VERSION ""

NS_ :

BS_:

BU_: ECU_CHASSIS ECU_ACTUATOR

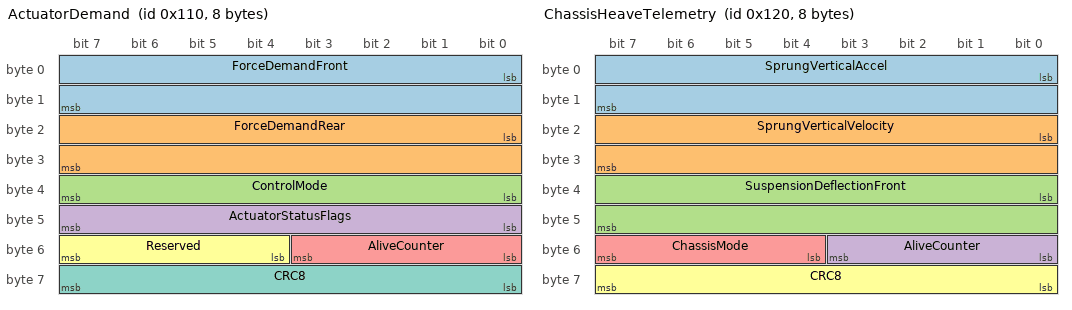
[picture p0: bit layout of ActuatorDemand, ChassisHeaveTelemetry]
BO_ 272 ActuatorDemand: 8 ECU_CHASSIS
 SG_ ForceDemandFront : 0|16@1- (0.1,0) [-2500|2500] "N" ECU_ACTUATOR
 SG_ ForceDemandRear : 16|16@1- (0.1,0) [-2500|2500] "N" ECU_ACTUATOR
 SG_ ControlMode : 32|8@1+ (1,0) [0|3] "" ECU_ACTUATOR
 SG_ ActuatorStatusFlags : 40|8@1+ (1,0) [0|255] "" ECU_ACTUATOR
 SG_ AliveCounter : 48|4@1+ (1,0) [0|15] "" ECU_ACTUATOR
 SG_ Reserved : 52|4@1+ (1,0) [0|15] "" ECU_ACTUATOR
 SG_ CRC8 : 56|8@1+ (1,0) [0|255] "" ECU_ACTUATOR

BO_ 288 ChassisHeaveTelemetry: 8 ECU_CHASSIS
 SG_ SprungVerticalAccel : 0|16@1- (0.001,0) [-30|30] "m/s^2" ECU_ACTUATOR
 SG_ SprungVerticalVelocity : 16|16@1- (0.0001,0) [-3|3] "m/s" ECU_ACTUATOR
 SG_ SuspensionDeflectionFront : 32|16@1- (0.00001,0) [-0.1|0.1] "m" ECU_ACTUATOR
 SG_ AliveCounter : 48|4@1+ (1,0) [0|15] "" ECU_ACTUATOR
 SG_ ChassisMode : 52|4@1+ (1,0) [0|15] "" ECU_ACTUATOR
 SG_ CRC8 : 56|8@1+ (1,0) [0|255] "" ECU_ACTUATOR

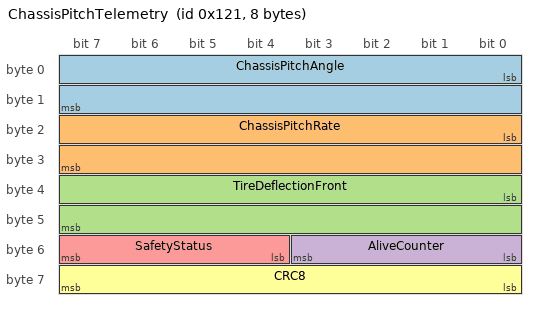
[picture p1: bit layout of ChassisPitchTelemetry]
BO_ 289 ChassisPitchTelemetry: 8 ECU_CHASSIS
 SG_ ChassisPitchAngle : 0|16@1- (0.0001,0) [-1|1] "rad" ECU_ACTUATOR
 SG_ ChassisPitchRate : 16|16@1- (0.0001,0) [-2|2] "rad/s" ECU_ACTUATOR
 SG_ TireDeflectionFront : 32|16@1- (0.00001,0) [-0.1|0.1] "m" ECU_ACTUATOR
 SG_ AliveCounter : 48|4@1+ (1,0) [0|15] "" ECU_ACTUATOR
 SG_ SafetyStatus : 52|4@1+ (1,0) [0|15] "" ECU_ACTUATOR
 SG_ CRC8 : 56|8@1+ (1,0) [0|255] "" ECU_ACTUATOR

CM_ BO_ 272 "Chassis Controller Actuator Command (100 Hz / 10 ms cycle)";
CM_ BO_ 288 "Chassis Heave Dynamics Telemetry (100 Hz / 10 ms cycle)";
CM_ BO_ 289 "Chassis Pitch and Road Contact Telemetry (100 Hz / 10 ms cycle)";

BA_DEF_ BO_ "GenMsgCycleTime" INT 0 65535;
BA_DEF_DEF_ "GenMsgCycleTime" 10;
